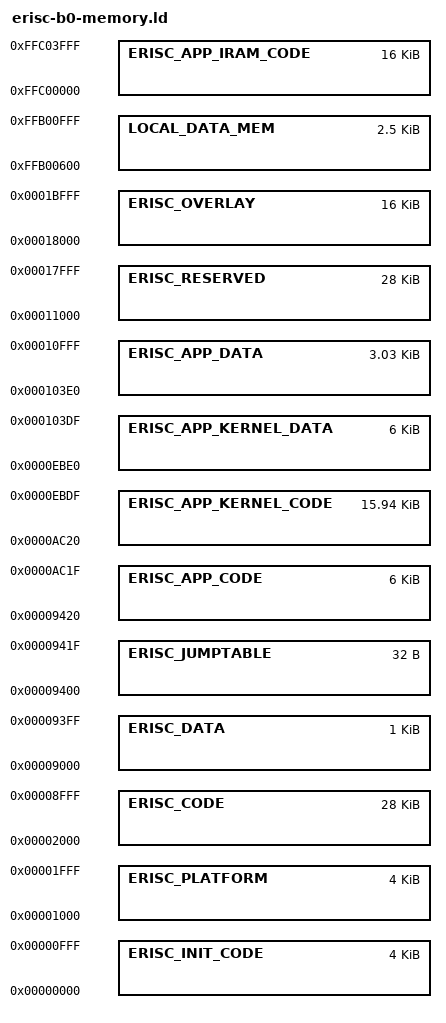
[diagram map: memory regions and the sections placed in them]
/* SPDX-FileCopyrightText: © 2023 Tenstorrent Inc.
 * SPDX-License-Identifier: Apache-2.0
 *
 */

MEMORY
{
    LOCAL_DATA_MEM : ORIGIN = 0xFFB00600, LENGTH = 2560
    ERISC_INIT_CODE : ORIGIN = 0x00000000, LENGTH = 4K
    ERISC_PLATFORM : ORIGIN = 0x00001000, LENGTH = 4K
    ERISC_CODE : ORIGIN = 0x00002000, LENGTH = 28K
    ERISC_DATA : ORIGIN = 0x00009000, LENGTH = 1K
    ERISC_JUMPTABLE : ORIGIN = 0x00009400, LENGTH = 32


    ERISC_APP_CODE : ORIGIN = 0x00009420, LENGTH = 6K

    ERISC_APP_KERNEL_CODE : ORIGIN = 0x0000AC20, LENGTH = 16320
    ERISC_APP_KERNEL_DATA : ORIGIN = 0x0000EBE0, LENGTH = 6144
    ERISC_APP_DATA : ORIGIN = 0x000103E0, LENGTH = 3104
    ERISC_RESERVED : ORIGIN = 0x11000, LENGTH = 28K
    ERISC_OVERLAY : ORIGIN = 0x18000, LENGTH = 16K
    ERISC_APP_IRAM_CODE : ORIGIN = 0xFFC00000, LENGTH = 16K
}
